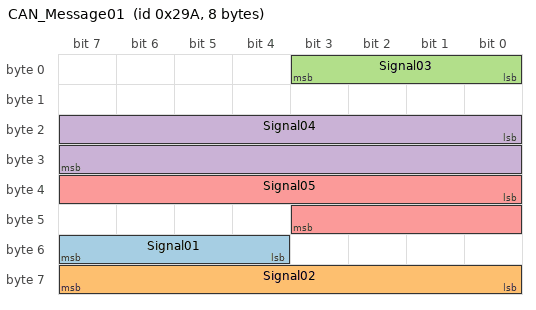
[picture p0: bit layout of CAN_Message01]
BO_ 666 CAN_Message01: 8 ECU1
 SG_ Signal01: 52|4@1+  (1,0) [0|15] ""  ECU2
 SG_ Signal02: 56|8@1+  (1,0) [0|255] ""  ECU2
 SG_ Signal03: 0|4@1+   (1,0) [0|15] "" ECU2,ECU3
 SG_ Signal04: 16|16@1+ (1,-32767) [-32767|32768] "rpm" ECU2
 SG_ Signal05: 32|12@1+ (0.25,-511) [-511|512.75] "Nm" ECU5
